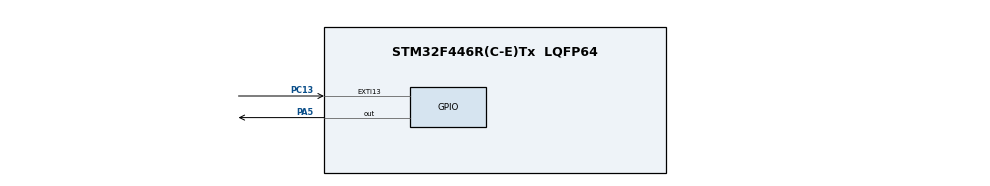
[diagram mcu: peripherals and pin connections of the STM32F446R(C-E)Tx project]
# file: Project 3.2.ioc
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Mcu.Family=STM32F4
Mcu.Name=STM32F446R(C-E)Tx
Mcu.Package=LQFP64
NVIC.EXTI15_10_IRQn=true\:0\:0\:false\:false\:true\:true\:true\:true
NVIC.PriorityGroup=NVIC_PRIORITYGROUP_4
PA5.Signal=GPIO_Output
PC13.GPIO_ModeDefaultEXTI=GPIO_MODE_IT_FALLING
PC13.Signal=GPXTI13
ProjectManager.HeapSize=0x200
ProjectManager.StackSize=0x400
ProjectManager.TargetToolchain=STM32CubeIDE
RCC.CortexFreq_Value=16000000
RCC.USBFreq_Value=96000000
RCC.VCOOutputFreq_Value=192000000
board=custom

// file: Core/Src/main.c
/* USER CODE BEGIN Header */
/**
  ******************************************************************************
  * @file           : main.c
  * @brief          : Main program body
  ******************************************************************************
  * @attention
  *
  * Copyright (c) 2026 STMicroelectronics.
  * All rights reserved.
  *
  * This software is licensed under terms that can be found in the LICENSE file
  * in the root directory of this software component.
  * If no LICENSE file comes with this software, it is provided AS-IS.
  *
  ******************************************************************************
  */
/* USER CODE END Header */
#include "main.h"

void SystemClock_Config(void);
static void MX_GPIO_Init(void);

/* USER CODE BEGIN 0 */

/* HAL EXTI callback -- called from stm32f4xx_hal_gpio.c ISR stub */
void HAL_GPIO_EXTI_Callback(uint16_t GPIO_Pin)
{
    if (GPIO_Pin == GPIO_PIN_13)  /* PC13 = B1 user button */
    {
        HAL_GPIO_TogglePin(GPIOA, GPIO_PIN_5); /* Toggle LED LD2 */
    }
}

/* USER CODE END 0 */

int main(void)
{

    /* MCU Configuration--------------------------------------------------------*/
    HAL_Init();

    /* Configure the system clock */
    SystemClock_Config();

    /* Initialize all configured peripherals */
    MX_GPIO_Init();

    /* Infinite loop */
    while (1)
    {
        __WFI(); /* Main loop does nothing; ISR handles all work */
    }
}

void SystemClock_Config(void)
{
    RCC_OscInitTypeDef RCC_OscInitStruct = {0};
    RCC_ClkInitTypeDef RCC_ClkInitStruct = {0};

    __HAL_RCC_PWR_CLK_ENABLE();
    __HAL_PWR_VOLTAGESCALING_CONFIG(PWR_REGULATOR_VOLTAGE_SCALE3);

    RCC_OscInitStruct.OscillatorType = RCC_OSCILLATORTYPE_HSI;
    RCC_OscInitStruct.HSIState = RCC_HSI_ON;
    RCC_OscInitStruct.HSICalibrationValue = RCC_HSICALIBRATION_DEFAULT;
    RCC_OscInitStruct.PLL.PLLState = RCC_PLL_NONE;
    if (HAL_RCC_OscConfig(&RCC_OscInitStruct) != HAL_OK)
    {
        Error_Handler();
    }

    RCC_ClkInitStruct.ClockType = RCC_CLOCKTYPE_HCLK|RCC_CLOCKTYPE_SYSCLK
                                |RCC_CLOCKTYPE_PCLK1|RCC_CLOCKTYPE_PCLK2;
    RCC_ClkInitStruct.SYSCLKSource = RCC_SYSCLKSOURCE_HSI;
    RCC_ClkInitStruct.AHBCLKDivider = RCC_SYSCLK_DIV1;
    RCC_ClkInitStruct.APB1CLKDivider = RCC_HCLK_DIV1;
    RCC_ClkInitStruct.APB2CLKDivider = RCC_HCLK_DIV1;
    if (HAL_RCC_ClockConfig(&RCC_ClkInitStruct, FLASH_LATENCY_0) != HAL_OK)
    {
        Error_Handler();
    }
}

static void MX_GPIO_Init(void)
{
    GPIO_InitTypeDef GPIO_InitStruct = {0};

    /* GPIO Ports Clock Enable */
    __HAL_RCC_GPIOC_CLK_ENABLE();
    __HAL_RCC_GPIOA_CLK_ENABLE();

    /* Configure GPIO pin Output Level (PA5 LED) */
    HAL_GPIO_WritePin(GPIOA, GPIO_PIN_5, GPIO_PIN_RESET);

    /* Configure GPIO pin : PC13 (User Button B1) */
    GPIO_InitStruct.Pin = GPIO_PIN_13;
    GPIO_InitStruct.Mode = GPIO_MODE_IT_FALLING;
    GPIO_InitStruct.Pull = GPIO_NOPULL;
    HAL_GPIO_Init(GPIOC, &GPIO_InitStruct);

    /* Configure GPIO pin : PA5 (LED LD2) */
    GPIO_InitStruct.Pin = GPIO_PIN_5;
    GPIO_InitStruct.Mode = GPIO_MODE_OUTPUT_PP;
    GPIO_InitStruct.Pull = GPIO_NOPULL;
    GPIO_InitStruct.Speed = GPIO_SPEED_FREQ_LOW;
    HAL_GPIO_Init(GPIOA, &GPIO_InitStruct);

    /* EXTI interrupt init */
    HAL_NVIC_SetPriority(EXTI15_10_IRQn, 0, 0);
    HAL_NVIC_EnableIRQ(EXTI15_10_IRQn);
}

void Error_Handler(void)
{
    __disable_irq();
    while (1)
    {
    }
}
